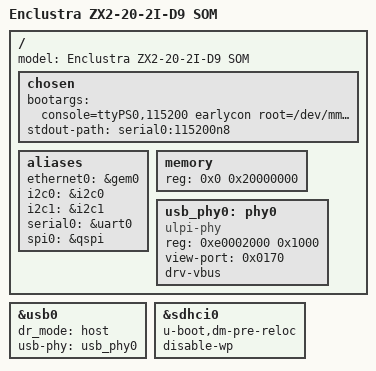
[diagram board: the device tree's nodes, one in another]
/dts-v1/;

#include "zynq-7000.dtsi"
#include "zynq_enclustra_common.dtsi"
#include "zynq_enclustra_mars_zx2.dtsi"
#include "zynq_enclustra_qspi_parts.dtsi"

/ {
        model = "Enclustra ZX2-20-2I-D9 SOM";

        chosen {
                bootargs = "console=ttyPS0,115200 earlycon root=/dev/mmcblk0p2 rw rootfstype=ext4 rootwait";
                stdout-path = "serial0:115200n8";
        };

        aliases {
                ethernet0 = &gem0;
                i2c0 = &i2c0;
                i2c1 = &i2c1;
                serial0 = &uart0;
                spi0 = &qspi;
        };

        memory {
                device_type = "memory";
                reg = <0x0 0x20000000>;
        };

        usb_phy0: phy0 {
                compatible = "ulpi-phy";
                #phy-cells = <0>;
                reg = <0xe0002000 0x1000>;
                view-port = <0x0170>;
                drv-vbus;
        };
};

&usb0 {
        status = "okay";
        dr_mode = "host";
        usb-phy = <&usb_phy0>;
};

&sdhci0 {
        u-boot,dm-pre-reloc;
        status = "okay";
        disable-wp;
};
